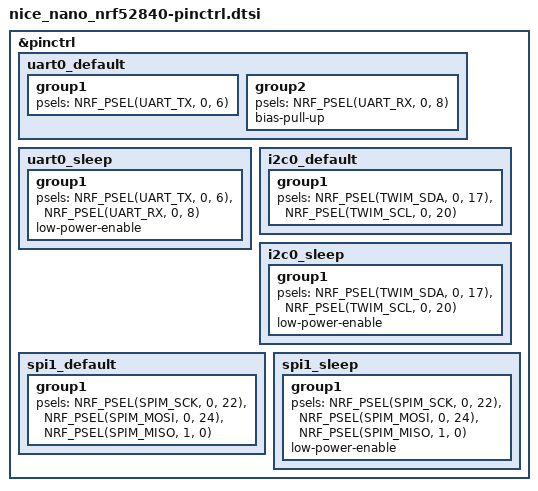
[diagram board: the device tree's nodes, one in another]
/*
 * Copyright (c) nice!nano community
 * SPDX-License-Identifier: Apache-2.0
 *
 * nice!nano v2 pin-control definitions.
 * Adjust pin numbers to match your hardware revision if needed.
 */

&pinctrl {
	uart0_default: uart0_default {
		group1 {
			psels = <NRF_PSEL(UART_TX, 0, 6)>;
		};
		group2 {
			psels = <NRF_PSEL(UART_RX, 0, 8)>;
			bias-pull-up;
		};
	};

	uart0_sleep: uart0_sleep {
		group1 {
			psels = <NRF_PSEL(UART_TX, 0, 6)>,
			        <NRF_PSEL(UART_RX, 0, 8)>;
			low-power-enable;
		};
	};

	i2c0_default: i2c0_default {
		group1 {
			psels = <NRF_PSEL(TWIM_SDA, 0, 17)>,
			        <NRF_PSEL(TWIM_SCL, 0, 20)>;
		};
	};

	i2c0_sleep: i2c0_sleep {
		group1 {
			psels = <NRF_PSEL(TWIM_SDA, 0, 17)>,
			        <NRF_PSEL(TWIM_SCL, 0, 20)>;
			low-power-enable;
		};
	};

	spi1_default: spi1_default {
		group1 {
			psels = <NRF_PSEL(SPIM_SCK,  0, 22)>,
			        <NRF_PSEL(SPIM_MOSI, 0, 24)>,
			        <NRF_PSEL(SPIM_MISO, 1,  0)>;
		};
	};

	spi1_sleep: spi1_sleep {
		group1 {
			psels = <NRF_PSEL(SPIM_SCK,  0, 22)>,
			        <NRF_PSEL(SPIM_MOSI, 0, 24)>,
			        <NRF_PSEL(SPIM_MISO, 1,  0)>;
			low-power-enable;
		};
	};
};
